# G32M3101 register map
File version: 1.0
CPU: CM0+ r0p1, little endian, MPU, no FPU, 2 interrupt priority bits
Registers are 32-bit, read-write, reset 0x0 unless marked. A register's access mark holds for its fields unless they carry their own. Offsets are from the block's base; [hi:lo] are bit positions; {n}, {i} and the like mark numbered series.

## SCU — System configuration controller
Base 0x40020400
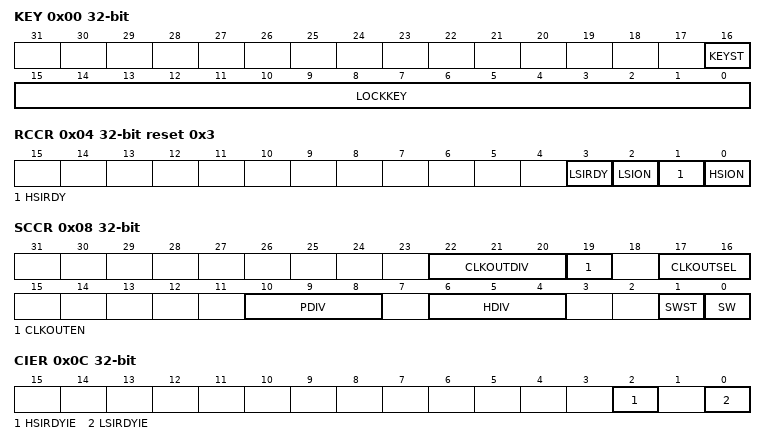
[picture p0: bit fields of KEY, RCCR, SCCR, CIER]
0x00 KEY access per field
  [16] KEYST rw — System register KEY protection status bit.
  [15:0] LOCKKEY wo — Configuration of password protection for system register write operations.
0x04 RCCR access per field reset 0x3
  [3] LSIRDY ro — LSI READY FLAG
  [2] LSION rw — LSI enable
  [1] HSIRDY ro — HSI READY FLAG
  [0] HSION rw — HSI enable
0x08 SCCR access per field
  [22:20] CLKOUTDIV rw — CLKOUT clock frequency output
  [19] CLKOUTEN rw — Clock output enable
  [17:16] CLKOUTSEL rw — CLKOUT clock output selection
  [10:8] PDIV rw — APB clock division.
  [6:4] HDIV rw — AHB clock division.
  [1] SWST ro — System Clock Status
  [0] SW rw — System Clock Selection
0x0C CIER
  [2] HSIRDYIE — HSI-ready interrupt enable
  [0] LSIRDYIE — LSI-ready interrupt enable
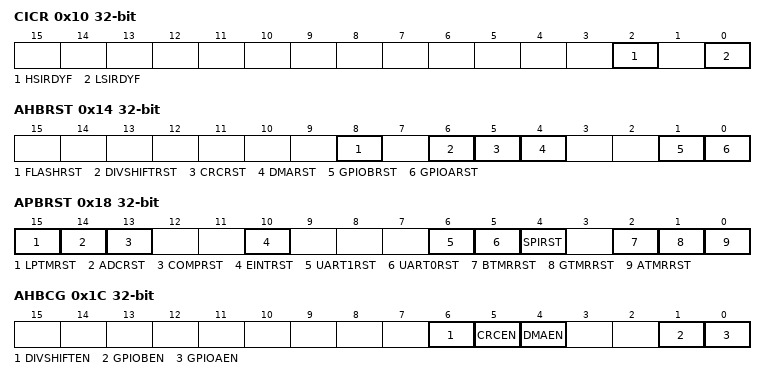
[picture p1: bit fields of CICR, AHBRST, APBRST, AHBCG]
0x10 CICR
  [2] HSIRDYF — HSI-ready flag
  [0] LSIRDYF — LSI-ready flag
0x14 AHBRST
  [8] FLASHRST — FLASH module reset
  [6] DIVSHIFTRST — DIV module reset
  [5] CRCRST — CRC module reset
  [4] DMARST — DMA module reset
  [1] GPIOBRST — GPIOB module reset
  [0] GPIOARST — GPIOA module reset
0x18 APBRST
  [15] LPTMRST — LPTMR module reset
  [14] ADCRST — ADC module reset
  [13] COMPRST — COMP module reset
  [10] EINTRST — EINT module reset
  [6] UART1RST — UART1 module reset
  [5] UART0RST — UART0 module reset
  [4] SPIRST — SPI module reset
  [2] BTMRRST — TMR2 module reset
  [1] GTMRRST — TMR1 module reset
  [0] ATMRRST — TMR0 module reset
0x1C AHBCG
  [6] DIVSHIFTEN — DIV clock enable
  [5] CRCEN — CRC clock enable
  [4] DMAEN — DMA clock enable
  [1] GPIOBEN — GPIOB clock enable
  [0] GPIOAEN — GPIOA clock enable
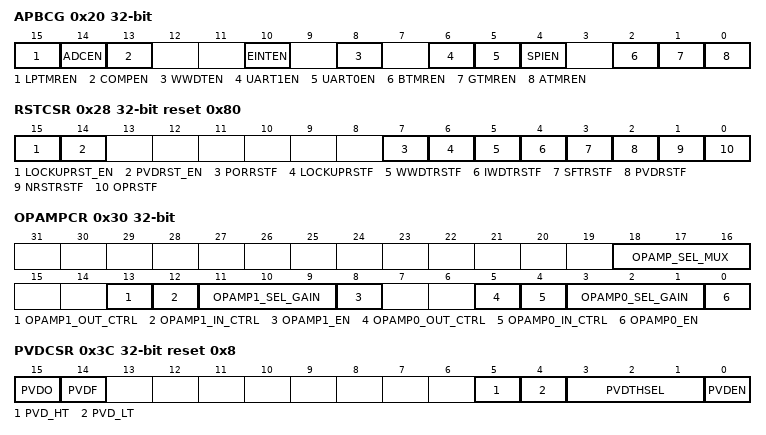
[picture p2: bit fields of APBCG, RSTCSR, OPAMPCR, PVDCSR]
0x20 APBCG
  [15] LPTMREN — LPTMR module enable
  [14] ADCEN — ADC module enable
  [13] COMPEN — COMP module enable
  [10] EINTEN — EINT module enable
  [8] WWDTEN — UART1 module enable
  [6] UART1EN — UART1 module enable
  [5] UART0EN — UART0 module enable
  [4] SPIEN — SPI module enable
  [2] BTMREN — TMR2 module enable
  [1] GTMREN — TMR1 module enable
  [0] ATMREN — TMR0 module enable
0x28 RSTCSR reset 0x80
  [15] LOCKUPRST_EN — /
  [14] PVDRST_EN — /
  [7] PORRSTF — Power reset caused by.
  [6] LOCKUPRSTF — /
  [5] WWDTRSTF — Window watchdog reset.
  [4] IWDTRSTF — Reset caused by independent watchdog.
  [3] SFTRSTF — Software-induced reset
  [2] PVDRSTF — /
  [1] NRSTRSTF — Reset caused by external RST pin.
  [0] OPRSTF — Reset caused by opload.
0x2C ADCCR
  [1:0] ADCCLK_DIV — /
0x30 OPAMPCR
  [18:16] OPAMP_SEL_MUX — /
  [13] OPAMP1_OUT_CTRL — /
  [12] OPAMP1_IN_CTRL — /
  [11:9] OPAMP1_SEL_GAIN — /
  [8] OPAMP1_EN — /
  [5] OPAMP0_OUT_CTRL — /
  [4] OPAMP0_IN_CTRL — /
  [3:1] OPAMP0_SEL_GAIN — /
  [0] OPAMP0_EN — /
0x3C PVDCSR reset 0x8
  [15] PVDO ro — /
  [14] PVDF — /
  [5] PVD_HT — /
  [4] PVD_LT — /
  [3:1] PVDTHSEL — /
  [0] PVDEN — /
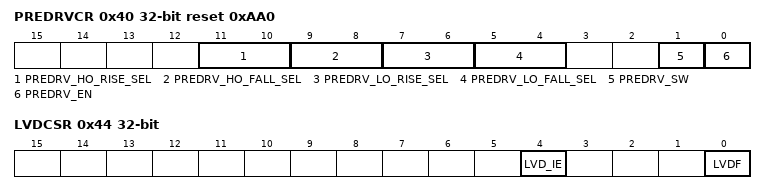
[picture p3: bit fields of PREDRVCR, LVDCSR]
0x40 PREDRVCR reset 0xAA0
  [11:10] PREDRV_HO_RISE_SEL — /
  [9:8] PREDRV_HO_FALL_SEL — /
  [7:6] PREDRV_LO_RISE_SEL — /
  [5:4] PREDRV_LO_FALL_SEL — /
  [1] PREDRV_SW — /
  [0] PREDRV_EN — /
0x44 LVDCSR
  [4] LVD_IE — /
  [0] LVDF ro — /

## FLASH — Flash memory controller
Base 0x40020800
0x00 RKEY — /
  [0] RKEY — Status 1: Unlocked. Status 0: Locked
0x04 MKEY — /
  [0] MKEY — Status 1: Unlocked. Status 0: Locked
0x0C NVR5KEY — /
  [0] NVR5KEY — Status 1: Unlocked. Status 0: Locked
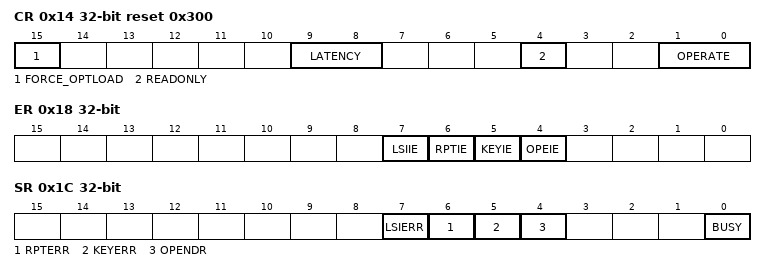
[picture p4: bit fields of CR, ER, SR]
0x14 CR reset 0x300 — /
  [15] FORCE_OPTLOAD — The option byte is forcibly updated. When the data written to the high 16 bits is 0xa5a5 at the same time, the bit can be written as 1. When it is written as 1, the bit forcibly reloads the option byte, which will trigger a system reset. 0: Invalid 1: Valid
  [9:8] LATENCY — The default value for the delay period on power-up at 64mhz (48mhz) is 2.
  [4] READONLY — Flash ip read-only control, cannot be erased/written.
  [1:0] OPERATE — Flash operation type configuration
0x18 ER — /
  [7] LSIIE — LSI Erase Error Interrupt Enable
  [6] RPTIE — FLASH Read/Write Protection Interrupt Enable
  [5] KEYIE — Flash KEY Error Interrupt Enable
  [4] OPEIE — FLSAH Erase End Interrupt Enable
0x1C SR access per field — /
  [7] LSIERR rw — LSI erase error interrupt, system clock switches to LSI, erasing flash, invalid.
  [6] RPTERR rw — FLASH read and write protection interrupt
  [5] KEYERR rw — Flash KEY error interrupt, not unlocking flash erase.
  [4] OPENDR rw — FLASH erase finish interrupt
  [0] BUSY ro — FLASH erase BUSY bit

## GPIOA — General-purpose I/Os
Base 0x40021400
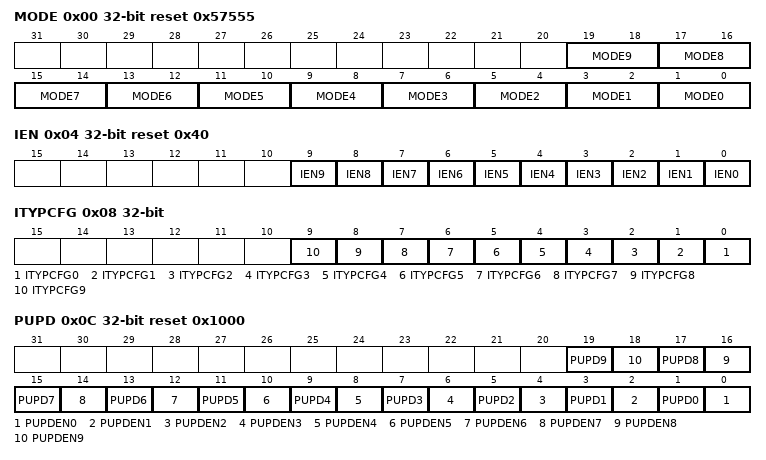
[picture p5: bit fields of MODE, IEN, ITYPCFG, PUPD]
0x00 MODE reset 0x57555
  [2n+1:2n] MODE{n} (n=0..9) — /
0x04 IEN reset 0x40
  [n] IEN{n} (n=0..9) — /
0x08 ITYPCFG
  [n] ITYPCFG{n} (n=0..9) — /
0x0C PUPD reset 0x1000
  [2n+1] PUPD{n} (n=0..9) — /
  [2n] PUPDEN{n} (n=0..9) — /
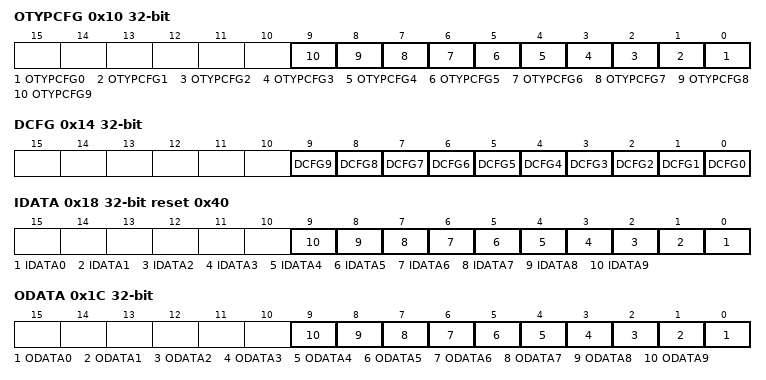
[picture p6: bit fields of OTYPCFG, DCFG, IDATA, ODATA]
0x10 OTYPCFG
  [n] OTYPCFG{n} (n=0..9) — /
0x14 DCFG
  [n] DCFG{n} (n=0..9) — /
0x18 IDATA ro reset 0x40
  [n] IDATA{n} (n=0..9) — /
0x1C ODATA
  [n] ODATA{n} (n=0..9) — /
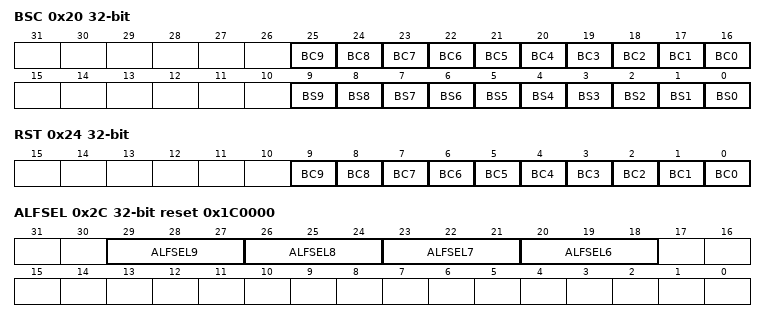
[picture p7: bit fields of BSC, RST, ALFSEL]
0x20 BSC wo
  [n+16] BC{n} (n=0..9) — /
  [n] BS{n} (n=0..9) — /
0x24 RST wo
  [n] BC{n} (n=0..9) — /
0x28 LOCK
  [31:0] LOCKKEY — /
0x2C ALFSEL reset 0x1C0000
  [3n+2:3n] ALFSEL{n} (n=6..9) — /
0x34 FLT
  [6] FLTEN6 — /

## GPIOB — General-purpose I/Os
Base 0x40021800
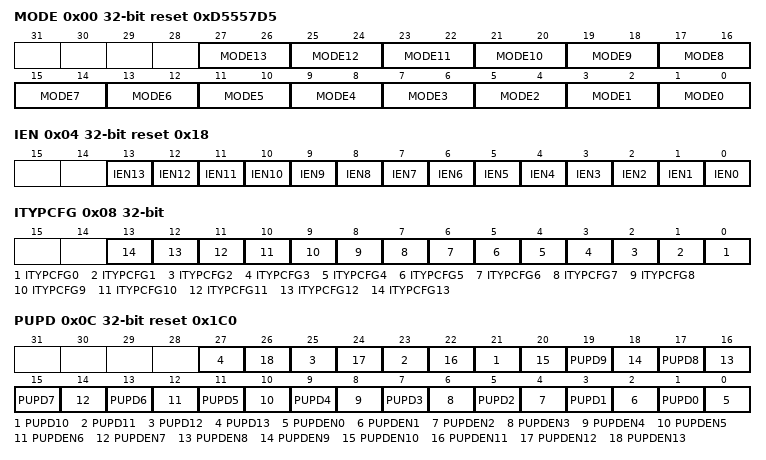
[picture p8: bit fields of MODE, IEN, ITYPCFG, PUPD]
0x00 MODE reset 0xD5557D5
  [2n+1:2n] MODE{n} (n=0..13) — /
0x04 IEN reset 0x18
  [n] IEN{n} (n=0..13) — /
0x08 ITYPCFG
  [n] ITYPCFG{n} (n=0..13) — /
0x0C PUPD reset 0x1C0
  [2n+1] PUPD{n} (n=0..13) — /
  [2n] PUPDEN{n} (n=0..13) — /
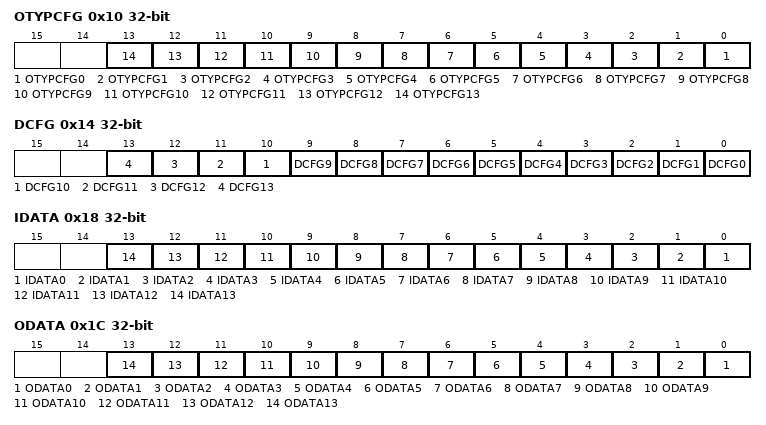
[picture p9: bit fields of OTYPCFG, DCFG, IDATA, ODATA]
0x10 OTYPCFG
  [n] OTYPCFG{n} (n=0..13) — /
0x14 DCFG
  [n] DCFG{n} (n=0..13) — /
0x18 IDATA ro
  [n] IDATA{n} (n=0..13) — /
0x1C ODATA
  [n] ODATA{n} (n=0..13) — /
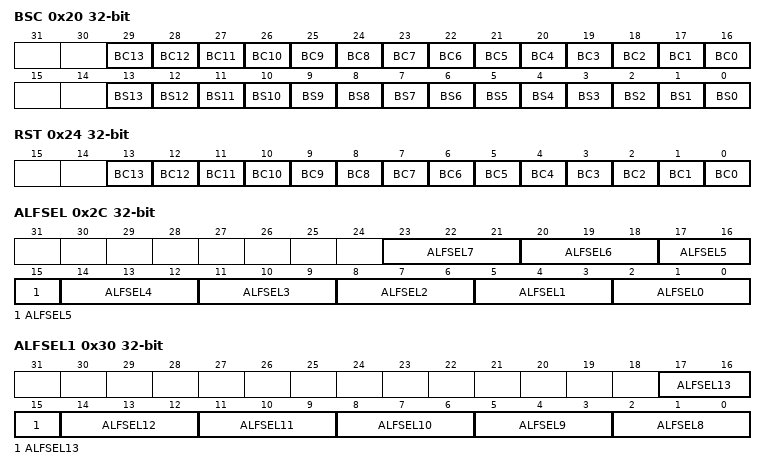
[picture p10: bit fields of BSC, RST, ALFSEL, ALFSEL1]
0x20 BSC wo
  [n+16] BC{n} (n=0..13) — /
  [n] BS{n} (n=0..13) — /
0x24 RST wo
  [n] BC{n} (n=0..13) — /
0x28 LOCK
  [31:0] LOCKKEY — /
0x2C ALFSEL
  [3n+2:3n] ALFSEL{n} (n=0..7) — /
0x30 ALFSEL1
  [3n-22:3n-24] ALFSEL{n} (n=8..13) — /

## EINT — External interrupt/event controller
Base 0x40009000
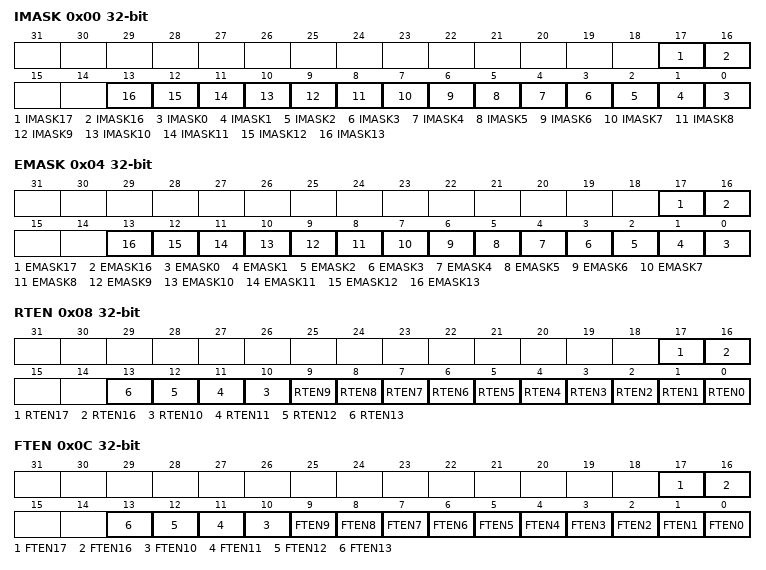
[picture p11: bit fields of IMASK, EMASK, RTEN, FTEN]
0x00 IMASK
  [17] IMASK17 — /
  [16] IMASK16 — /
  [n] IMASK{n} (n=0..13) — /
0x04 EMASK
  [17] EMASK17 — /
  [16] EMASK16 — /
  [n] EMASK{n} (n=0..13) — /
0x08 RTEN
  [17] RTEN17 — /
  [16] RTEN16 — /
  [n] RTEN{n} (n=0..13) — /
0x0C FTEN
  [17] FTEN17 — /
  [16] FTEN16 — /
  [n] FTEN{n} (n=0..13) — /
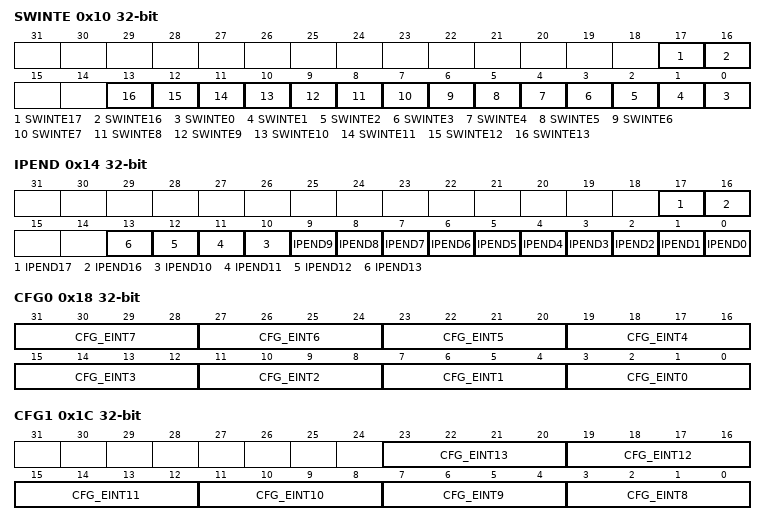
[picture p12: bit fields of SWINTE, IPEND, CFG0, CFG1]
0x10 SWINTE
  [17] SWINTE17 — /
  [16] SWINTE16 — /
  [n] SWINTE{n} (n=0..13) — /
0x14 IPEND
  [17] IPEND17 — /
  [16] IPEND16 — /
  [n] IPEND{n} (n=0..13) — /
0x18 CFG0
  [4n+3:4n] CFG_EINT{n} (n=0..7) — /
0x1C CFG1
  [4n-29:4n-32] CFG_EINT{n} (n=8..13) — /

## DIV
Base 0x40021000
0x00 DVDR — Dividend register
  [31:0] DIVIDEND
0x04 DVSR reset 0x1 — Divisor Register
  [31:0] DIVISOR
0x08 QUOTR ro — Quotient register
  [31:0] QUOTIENT
0x0C RMDR — Remainder register
  [31:0] REMAINDER
0x14 CR reset 0x1 — Control register
  [0] USIGNEN — Enable unsigned division
